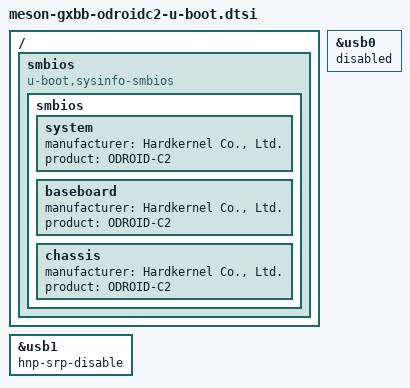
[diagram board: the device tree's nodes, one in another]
// SPDX-License-Identifier: (GPL-2.0+ OR MIT)
/*
 * Copyright (c) 2019 BayLibre, SAS.
 * Author: Neil Armstrong <narmstrong@baylibre.com>
 */

#include "meson-gx-u-boot.dtsi"

/ {
	smbios {
		compatible = "u-boot,sysinfo-smbios";

		smbios {
			system {
				manufacturer = "Hardkernel Co., Ltd.";
				product = "ODROID-C2";
			};

			baseboard {
				manufacturer = "Hardkernel Co., Ltd.";
				product = "ODROID-C2";
			};

			chassis {
				manufacturer = "Hardkernel Co., Ltd.";
				product = "ODROID-C2";
			};
		};
	};
};

&usb0 {
	status = "disabled";
};

&usb1 {
	hnp-srp-disable;
};
